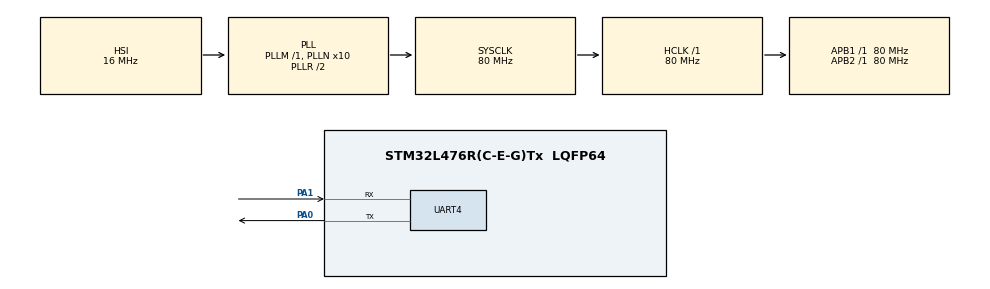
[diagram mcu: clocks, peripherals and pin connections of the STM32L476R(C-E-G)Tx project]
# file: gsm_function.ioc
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Mcu.Family=STM32L4
Mcu.Name=STM32L476R(C-E-G)Tx
Mcu.Package=LQFP64
NVIC.PriorityGroup=NVIC_PRIORITYGROUP_4
NVIC.UART4_IRQn=true\:0\:0\:false\:false\:true\:true\:true\:true
PA0.Mode=Asynchronous
PA0.Signal=UART4_TX
PA1.Mode=Asynchronous
PA1.Signal=UART4_RX
ProjectManager.HeapSize=0x200
ProjectManager.StackSize=0x400
ProjectManager.TargetToolchain=STM32CubeIDE
RCC.ADCFreq_Value=64000000
RCC.AHBFreq_Value=80000000
RCC.APB1Freq_Value=80000000
RCC.APB1TimFreq_Value=80000000
RCC.APB2Freq_Value=80000000
RCC.APB2TimFreq_Value=80000000
RCC.CortexFreq_Value=80000000
RCC.HCLKFreq_Value=80000000
RCC.HSE_VALUE=8000000
RCC.HSI_VALUE=16000000
RCC.MSI_VALUE=4000000
RCC.PLLN=10
RCC.PLLSourceVirtual=RCC_PLLSOURCE_HSI
RCC.PREFETCH_ENABLE=1
RCC.SYSCLKFreq_VALUE=80000000
RCC.SYSCLKSource=RCC_SYSCLKSOURCE_PLLCLK
RCC.USBFreq_Value=64000000
RCC.VCOOutputFreq_Value=160000000
board=NUCLEO-L476RG

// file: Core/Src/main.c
/* USER CODE BEGIN Header */
/**
  ******************************************************************************
  * @file           : main.c
  * @brief          : Main program body
  ******************************************************************************
  * @attention
  *
  * Copyright (c) 2024 STMicroelectronics.
  * All rights reserved.
  *
  * This software is licensed under terms that can be found in the LICENSE file
  * in the root directory of this software component.
  * If no LICENSE file comes with this software, it is provided AS-IS.
  *
  ******************************************************************************
  */
/* USER CODE END Header */
#include "main.h"
#include "stdio.h"
#include "string.h"
UART_HandleTypeDef huart4;
#define RXSIZE 200
uint8_t RxBuf[RXSIZE];
char *Rx_string;
char *str;
int _write(int file,char *ptr,int len)
{
    int i=0;
    for(i=0;i<len;i++)
    	ITM_SendChar((*ptr++));
    return len;
}

char* GSM_Send_AT_Command(char* AT_CMD)
{
	memset(RxBuf,0,200);
	printf("sent command %s\n",AT_CMD);
	HAL_UART_Transmit_IT(&huart4,(uint8_t*)AT_CMD, strlen(AT_CMD));
	HAL_UART_Receive(&huart4, RxBuf, 200,2000);
	printf("Received data %s\n",RxBuf);
	return (char *)RxBuf;

}
int GSM_TCP_init(void)
{
	int state =0,substate=0;
	while(1)
	{
		switch(state)
		{
			case 0:

					switch(substate)
					{
						case 0:
							str=GSM_Send_AT_Command("AT+CIPMODE?\r");
							if(strstr(str,"+CIPMODE: 0"))
							{

								state=1;
								substate=0;
							}
							else
							{
								substate=1;
							}
							break;
						case 1:
							str=GSM_Send_AT_Command("AT+CIPMODE=0\r");
							if(strstr(str,"OK"))
							{
								state=1;
								substate=0;
							}
							else
							{
								substate=0;
							}
							break;
					}
					break;

			case 1:

					switch(substate)
					{
						case 0:
							str=GSM_Send_AT_Command("AT+NETOPEN\r");
							if(strstr(str,"NETOPEN"))
							{
								state=2;
								substate=0;
							}
							else
							{
								substate=1;
							}
							break;
						case 1:
							str=GSM_Send_AT_Command("AT+NETOPEN\r");
							if(strstr(str,"opened"))
							{
									state=2;
									substate=0;
							}
							else
							{
									substate=0;
							}
					}
					break;

			case 2:
					return 0;
					break;
			default:
					return 1;
		}
	}
}
int GSM_APN_SET(void)
{

uint8_t state=0;
uint8_t substate=0;

 while (1)
  {
    /* USER CODE END WHILE */
	  switch(state)
	 	  {
	 	case 0:
	 		  switch(substate)
	   		  {
	   		  case 0:
	   			  Rx_string = GSM_Send_AT_Command("AT+COPS?\r");
	   			  if(strstr(Rx_string,"40449"))
	   			  {
	   				 state=1;
	   				printf("match found\n");
	   			  }
	   			  else
	   			  {
	   				  substate=1;
	   			  }
	   			  break;
	   		  case 1:
	   			  if(strstr(Rx_string,"405854"))
	   			  {
	   				  state=2;
	   				  substate=0;
	   			  	  printf("match found\n");
	   			  }
	   			  else
	   			  {
	   			  	  substate=0;
	   			  }
	   			  break;
			  case 2:
				  if(strstr(Rx_string,"ERROR"))
	   			  {
	   				  state=0;
	   			  	  substate=0;
	   			  }
	   			  else
	   			  {
	   			  	  state=0;
	   			  	  substate=0;
	   			  }
	   			  break;

	   		  default:
	   			  break;
	   		  }
	 		  break;
	 	case 1:
	 		  switch(substate)
	   		  {
	   		  case 0:
	   			  Rx_string = GSM_Send_AT_Command("AT+CGDCONT=1,\"IP\",\"airtelgprs.com\"\r");
	   			  if(strstr(Rx_string,"OK"))
	   			  {
	   				 state=2;
	   				 substate=0;
	   				printf("match found\n");
	   				return 0;
	   			  }
	   			  else
	   			  {
	   				  substate=1;
	   			  }
	   			  break;
	   		  case 1:
	   			  if(!(strncmp(Rx_string,"\r\nERROR\r\n",6)))
	   			  {
	   				  state=0;
	   			  	  substate=0;
	   			  }
	   			  else
	   			  {
	   			  	  state=0;
	   			  	  substate=0;
	   			  }
	   			  break;
	   		  default:
	   			  break;
	   		  }
	 		  break;
	 	case 2:
	 		  switch(substate)
	   		  {
	   		  case 0:
	   			  Rx_string = GSM_Send_AT_Command("AT+CGDCONT=1,\"IP\",\"jionet\"\r");
	   			  if(strstr(Rx_string,"OK"))
	   			  {
	   				 state=3;
	   				 substate=0;
	   				printf("match found\n");
					return 0;
	   			  }
	   			  else
	   			  {
	   				  substate=1;
	   			  }
	   			  break;
	   		  case 1:
			          if(!(strncmp(Rx_string,"\r\nERROR\r\n",6)))
	   			  {
	   			  	  substate=0;
	   			  	  state=2;
	   			  }
	   			  else
	   			  {
	   				  substate=0;
	   			  	  state=0;
	   			  }
	   			  break;
	   		  default:
	   			  break;
	   		  }
	 		  break;
	}
}
}

int GSM_SIM_INIT(void)
{

uint8_t state=0;
uint8_t substate=0;

 while (1)
  {
    /* USER CODE END WHILE */
	  switch(state)
	 	  {
	 	case 0:
	 		  switch(substate)
	   		  {
	   		  case 0:
	   			  Rx_string = GSM_Send_AT_Command("ATE0\r");
	   			  if(!(strncmp(Rx_string,"\r\nOK\r\n",6)))
	   			  {
	   				 state=1;
	   				printf("match found\n");
	   			  }
	   			  else
	   			  {
	   				  substate=1;
	   			  }
	   			  break;
	   		  case 1:
	   			  if(!(strncmp(Rx_string,"\r\nERROR\r\n",6)))
	   			  {
	   				  state=0;
	   			  	  substate=0;
	   			  }
	   			  else
	   			  {
	   			  	  state=0;
	   			  	  substate=0;
	   			  }
	   			  break;
	   		  default:
	   			  break;
	   		  }
	 		  break;
	 	case 1:
	 		  switch(substate)
	   		  {
	   		  case 0:
	   			  Rx_string = GSM_Send_AT_Command("AT+CPIN?\r");
	   			  if(strstr(Rx_string,"READY"))
	   			  {
	   				 state=2;
	   				 substate=0;
	   				printf("match found\n");
	   			  }
	   			  else
	   			  {
	   				  substate=1;
	   			  }
	   			  break;
	   		  case 1:
	   			  if(!(strncmp(Rx_string,"\r\nERROR\r\n",6)))
	   			  {
	   				  state=0;
	   			  	  substate=0;
	   			  }
	   			  else
	   			  {
	   			  	  state=0;
	   			  	  substate=0;
	   			  }
	   			  break;
	   		  default:
	   			  break;
	   		  }
	 		  break;
	 	case 2:
	 		  switch(substate)
	   		  {
	   		  case 0:
	   			  Rx_string = GSM_Send_AT_Command("AT+CSQ\r");
	   			  if(strstr(Rx_string,"99"))
	   			  {
	   				 state=3;
	   				 substate=0;
	   				printf("match found\n");
	   			  }
	   			  else
	   			  {
	   				  substate=1;
	   			  }
	   			  break;
	   		  case 1:
			          Rx_string = GSM_Send_AT_Command("AT+CFUN=1\r");
	   			  if(strstr(Rx_string,"0,1"))
	   			  {
	   			  	  substate=0;
	   			  	  state=2;
	   			  }
	   			  else
	   			  {
	   				  substate=0;
	   			  	  state=0;
	   			  }
	   			  break;
	   		  default:
	   			  break;
	   		  }
	 		  break;
	 case 3:
	 		  switch(substate)
	   		  {
	   		  case 0:
	   			  Rx_string = GSM_Send_AT_Command("AT+CMEE=2\r");
	   			  if(strstr(Rx_string,"OK"))
	   			  {
	   				 state=4;
	   				 substate=0;
	   				printf("match found\n");
	   			  }
	   			  else
	   			  {
	   				  substate=1;
	   			  }
	   			  break;
	   		  case 1:
	   			  if(!(strncmp(Rx_string,"\r\nERROR\r\n",6)))
	   			  {
	   				  state=0;
	   			  	  substate=0;
	   			  }
	   			  else
	   			  {
	   			  	  state=0;
	   			  	  substate=0;
	   			  }
	   			  break;
	   		  default:
	   			  break;
	   		  }
	 		  break;
	 	case 4:
	 		  switch(substate)
	   		  {
	   		  case 0:
	   			  Rx_string = GSM_Send_AT_Command("AT+CREG?\r");
	   			  if((strstr(Rx_string,"0,1"))||(strstr(Rx_string,"0,6")))
	   			  {
	   				 state=5;
	   				 substate=0;
	   				printf("match found\n");
	   			  }
	   			  else
	   			  {
	   				  substate=1;
	   			  }
	   			  break;
	   		  case 1:
	   			  if(!(strncmp(Rx_string,"\r\nERROR\r\n",6)))
	   			  {
	   				  state=0;
	   			  	  substate=0;
	   			  }
	   			  else
	   			  {
	   			  	  state=0;
	   			  	  substate=0;
	   			  }
	   			  break;
	   		  default:
	   			  break;
	   		  }
 			  break;
		case 5:
	 		  switch(substate)
	   		  {
	   		  case 0:
	   			  Rx_string = GSM_Send_AT_Command("AT+CGREG?\r");
	   			  if((strstr(Rx_string,"0,1"))||(strstr(Rx_string,"1,1")))
	   			  {
	   				 state=6;
	   				 substate=0;
	   				printf("match found\n");
	   			  }
	   			  else
	   			  {
	   				  substate=1;
	   			  }
	   			  break;
	   		  case 1:
				  Rx_string = GSM_Send_AT_Command("AT+CGREG=0\r");
	   			  if(strstr(Rx_string,"OK"))
	   			  {
	   				  state=5;
	   			  	  substate=0;
	   			  }
	   			  else
	   			  {
	   			  	  state=0;
	   			  	  substate=0;
	   			  }
	   			  break;
	   		  default:
	   			  break;
	   		  }
 			  break;
		case 6:
	 		  switch(substate)
	   		  {
	   		  case 0:
	   			  Rx_string = GSM_Send_AT_Command("AT+CPSI?\r");
	   			  if((strstr(Rx_string,"LTE,Online")))
	   			  {
	   				 state=0;
	   				 substate=0;
	   				printf("match found\n");
					return 0;
	   			  }
	   			  else
	   			  {
	   				  substate=1;
	   			  }
	   			  break;
	   		  case 1:
				  Rx_string = GSM_Send_AT_Command("AT+CGREG=1\r");
	   			  if(strstr(Rx_string,"OK"))
	   			  {
	   				  state=5;
	   			  	  substate=0;
	   			  }
	   			  else
	   			  {
	   			  	  state=0;
	   			  	  substate=0;
	   			  }
	   			  break;
	   		  default:
	   			  break;
	   		  }
 			  break;

	  default:
	 	 break;
  	}
	}
}

int GSM_Send_Data(uint8_t * data)
{
	int substate=0,cnt=0;
	char z=26;

		while(1)
		{			switch(substate)
					{
						case 0:
							str=GSM_Send_AT_Command("AT+CIPOPEN?\r");
							if(strstr(str,"139.59.78.252"))
							{
									//state=2;
									//substate=0;
									printf("ip OPEN WORKED\n");
									memset(RxBuf,0,200);
									HAL_UART_Transmit_IT(&huart4,(uint8_t*)"AT+CIPSEND=1\r", strlen("AT+CIPSEND=1\r"));
									HAL_UART_Receive(&huart4, RxBuf, 200,3000);
									printf("Received data1 %s\n",RxBuf);
									if(strstr(RxBuf,">"))
									{
									memset(RxBuf,0,200);
									//HAL_UART_Transmit_IT(&huart4,(uint8_t*)"$GPGSV,2,1,08,02,74,042,45,04,18,190,36,07,67,279,42,12,29,323,36*77", strlen("$GPGSV,2,1,08,02,74,042,45,04,18,190,36,07,67,279,42,12,29,323,36*77"));
									HAL_UART_Transmit_IT(&huart4,(uint8_t *)data,strlen(data));
									HAL_Delay(2000);
									HAL_UART_Transmit_IT(&huart4,&z,1);
									HAL_UART_Receive(&huart4, RxBuf, 200,3000);
									printf("Received data1 %s\n",RxBuf);
									memset(RxBuf,0,200);
									return 0;
									}
									else
									{
										substate=0;
									}

							}
							else
							{
								substate=1;
							}
							break;
						    case 1:
						    	str=GSM_Send_AT_Command("AT+CIPOPEN=1,\"TCP\",\"139.59.78.252\",49791\r");
						    	if(strstr(str,"+CIPOPEN: 1,0"))
						    	{
						    		//state=2;
						    		//substate=0;
						    		printf("ip OPEN WORKED\n");
						    		memset(RxBuf,0,200);
						    		HAL_UART_Transmit_IT(&huart4,(uint8_t*)"AT+CIPSEND=1\r", strlen("AT+CIPSEND=1\r"));
						    		HAL_UART_Receive(&huart4, RxBuf, 200,3000);
						    		printf("Received data1 %s\n",RxBuf);
						    		if(strstr(RxBuf,">"))
						    		{
						    		memset(RxBuf,0,200);
						    		HAL_UART_Transmit_IT(&huart4,(uint8_t *)data,strlen(data));
						    		HAL_Delay(2000);
						    		//HAL_UART_Transmit_IT(&huart4,(uint8_t*)"$GPGSV,2,1,08,02,74,042,45,04,18,190,36,07,67,279,42,12,29,323,36*77", strlen("$GPGSV,2,1,08,02,74,042,45,04,18,190,36,07,67,279,42,12,29,323,36*77"));
									HAL_UART_Transmit_IT(&huart4,&z,1);
									HAL_UART_Receive(&huart4, RxBuf, 200,3000);
						    		printf("Received data1 %s\n",RxBuf);
						    		 memset(RxBuf,0,200);
						    		return 0;
						    		}
						    		else
						    		{
						    			substate=1;
						    		}

							}
							else
							{
								substate=0;
								cnt++;
								if(cnt>5)
								{
									substate=2;
								}
							}
							break;
						case 2:
								return 1;  // GSM SEND failed
								break;

					}

		}

}

void SystemClock_Config(void);
static void MX_GPIO_Init(void);
static void MX_UART4_Init(void);

int main(void)
{

  /* MCU Configuration--------------------------------------------------------*/

  /* Reset of all peripherals, Initializes the Flash interface and the Systick. */
      HAL_Init();

  /* Configure the system clock */
  SystemClock_Config();

  /* Initialize all configured peripherals */
  MX_GPIO_Init();
  MX_UART4_Init();
  /* USER CODE BEGIN 2 */
  int ret;
  int ret1;
  /* USER CODE END 2 */

  /* Infinite loop */
  /* USER CODE BEGIN WHILE */

  ret= GSM_SIM_INIT();
  	 printf("Hello \n");
  	 if (ret==0)
  	 {
  		 printf("init worked\n");
  	 }
  	 else
  	 {
  			 printf("init NOT worked\n");
  	}
  	 ret = GSM_APN_SET();
  	 if (ret==0)
  		 {
  			 printf("APN SET worked\n");
  			ret1= GSM_TCP_init();
  		 }
  		 else
  		 {
  				 printf("APN SET NOT worked\n");
  		}
  	 if (ret1==0)
  	 	 {
  	 		 printf("tcp worked\n");

  	 	 }
  	 	 else
  	 	 {
  	 			 printf("tcp NOT worked\n");
  	 	}
  while (1)
  {
    /* USER CODE END WHILE */
	  //HAL_Delay(5000);

	 GSM_Send_Data("Hi Gopi ");
	/* if(ret==0)
	 {
		 printf("Sending worked\n");
	 }
	 else
	 {
		 printf("Sending not worked\n");
	 }*/
  }
}

void SystemClock_Config(void)
{
  RCC_OscInitTypeDef RCC_OscInitStruct = {0};
  RCC_ClkInitTypeDef RCC_ClkInitStruct = {0};

  /** Configure the main internal regulator output voltage
  */
  if (HAL_PWREx_ControlVoltageScaling(PWR_REGULATOR_VOLTAGE_SCALE1) != HAL_OK)
  {
    Error_Handler();
  }

  /** Initializes the RCC Oscillators according to the specified parameters
  * in the RCC_OscInitTypeDef structure.
  */
  RCC_OscInitStruct.OscillatorType = RCC_OSCILLATORTYPE_HSI;
  RCC_OscInitStruct.HSIState = RCC_HSI_ON;
  RCC_OscInitStruct.HSICalibrationValue = RCC_HSICALIBRATION_DEFAULT;
  RCC_OscInitStruct.PLL.PLLState = RCC_PLL_ON;
  RCC_OscInitStruct.PLL.PLLSource = RCC_PLLSOURCE_HSI;
  RCC_OscInitStruct.PLL.PLLM = 1;
  RCC_OscInitStruct.PLL.PLLN = 10;
  RCC_OscInitStruct.PLL.PLLP = RCC_PLLP_DIV7;
  RCC_OscInitStruct.PLL.PLLQ = RCC_PLLQ_DIV2;
  RCC_OscInitStruct.PLL.PLLR = RCC_PLLR_DIV2;
  if (HAL_RCC_OscConfig(&RCC_OscInitStruct) != HAL_OK)
  {
    Error_Handler();
  }

  /** Initializes the CPU, AHB and APB buses clocks
  */
  RCC_ClkInitStruct.ClockType = RCC_CLOCKTYPE_HCLK|RCC_CLOCKTYPE_SYSCLK
                              |RCC_CLOCKTYPE_PCLK1|RCC_CLOCKTYPE_PCLK2;
  RCC_ClkInitStruct.SYSCLKSource = RCC_SYSCLKSOURCE_PLLCLK;
  RCC_ClkInitStruct.AHBCLKDivider = RCC_SYSCLK_DIV1;
  RCC_ClkInitStruct.APB1CLKDivider = RCC_HCLK_DIV1;
  RCC_ClkInitStruct.APB2CLKDivider = RCC_HCLK_DIV1;

  if (HAL_RCC_ClockConfig(&RCC_ClkInitStruct, FLASH_LATENCY_4) != HAL_OK)
  {
    Error_Handler();
  }
}

static void MX_UART4_Init(void)
{

  huart4.Instance = UART4;
  huart4.Init.BaudRate = 115200;
  huart4.Init.WordLength = UART_WORDLENGTH_8B;
  huart4.Init.StopBits = UART_STOPBITS_1;
  huart4.Init.Parity = UART_PARITY_NONE;
  huart4.Init.Mode = UART_MODE_TX_RX;
  huart4.Init.HwFlowCtl = UART_HWCONTROL_NONE;
  huart4.Init.OverSampling = UART_OVERSAMPLING_16;
  huart4.Init.OneBitSampling = UART_ONE_BIT_SAMPLE_DISABLE;
  huart4.AdvancedInit.AdvFeatureInit = UART_ADVFEATURE_NO_INIT;
  if (HAL_UART_Init(&huart4) != HAL_OK)
  {
    Error_Handler();
  }

}

static void MX_GPIO_Init(void)
{

  /* GPIO Ports Clock Enable */
  __HAL_RCC_GPIOA_CLK_ENABLE();

}

void Error_Handler(void)
{
  __disable_irq();
  while (1)
  {
  }
}
